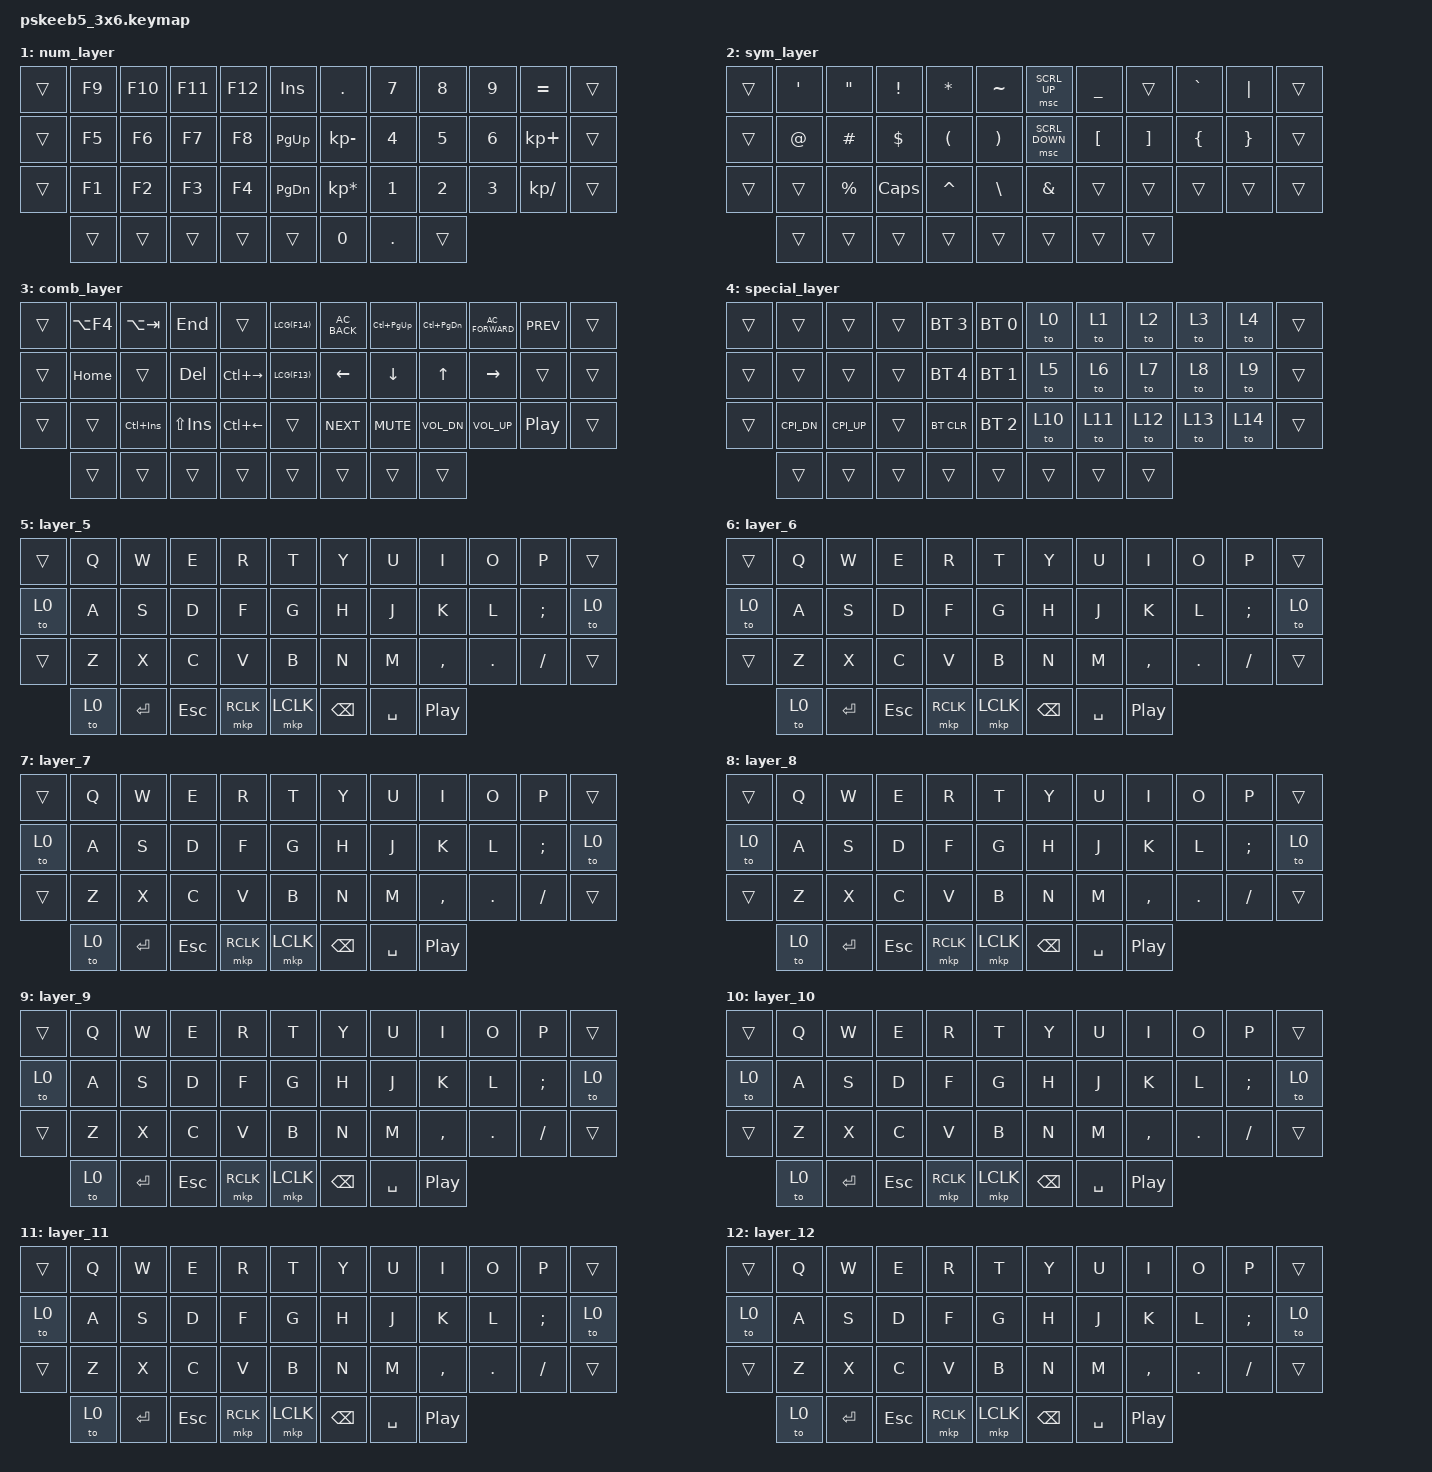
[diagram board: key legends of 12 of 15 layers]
// Copyright (c) 2022 The ZMK Contributors
// SPDX-License-Identifier: MIT

#include <behaviors.dtsi>
#include <dt-bindings/zmk/keys.h>
#include <dt-bindings/zmk/mouse.h>
#include <dt-bindings/zmk/bt.h>

// Home row mods macro
#define HRML(k1,k2,k3,k4) &ht LALT k1  &ht LSHFT k2  &ht LGUI k3  &ht LCTRL k4
#define HRMR(k1,k2,k3,k4) &ht RCTRL k1  &ht RGUI k2  &ht RSHFT k3  &ht RALT k4
#define LCS(keycode) APPLY_MODS(MOD_LCTL | MOD_LSFT, keycode)
#define LCG(keycode) APPLY_MODS(MOD_LCTL | MOD_LGUI, keycode)

// Rotary Endocer for mouse scrolling
#define ROT_MSC_VAL 280
#define ROT_MSC_SUP MOVE_Y(ROT_MSC_VAL)
#define ROT_MSC_SDN MOVE_Y(-ROT_MSC_VAL)
#define ROT_MSC_SLT MOVE_X(-ROT_MSC_VAL)
#define ROT_MSC_SRT MOVE_X(ROT_MSC_VAL)


/ {
// ╭──────┬──────┬──────┬──────┬──────┬──────╮  ╭──────┬──────┬──────┬──────┬──────┬──────╮
//    00     01     02     03     04     05        06     07     08     09     10     11
// ├──────┼──────┼──────┼──────┼──────┼──────┤  ├──────┼──────┼──────┼──────┼──────┼──────┤
//    12     13     14     15     16     17        18     19     20     21     22     23
// ├──────┼──────┼──────┼──────┼──────┼──────┤  ├──────┼──────┼──────┼──────┼──────┼──────┤
//    24     25     26     27     28     29        30     31     32     33     34     35
// ╰──────┴──────┴──────┼──────┼──────┼──────┤  ├──────┼──────┼──────┴──────┴──────┴──────╯
//                  36     37     38     39        40     41     42     43
//               ╰──────┴──────┴──────┴──────╯  ╰──────┴──────┴──────┴──────╯
    behaviors {
        ht: hold_tap {
            display-name = "Hold Tap";
            label = "hold_tap";
            compatible = "zmk,behavior-hold-tap";
            #binding-cells = <2>;
            flavor = "balanced";
            tapping-term-ms = <220>;
            quick-tap-ms = <200>;
            // global-quick-tap;
            tap-ms = <20>;
            bindings = <&kp>, <&kp>;
        };
        lt: layer_tap {
            display-name = "Layer Tap";
            compatible = "zmk,behavior-hold-tap";
            label = "LAYER_TAP";
            #binding-cells = <2>;
            // flavor = "balanced";
            tapping-term-ms = <200>;
            quick-tap-ms = <200>;
            // global-quick-tap;
            tap-ms = <20>;
            bindings = <&mo>, <&kp>;
        };
        rot_msc: sensor_rotate_msc {
            compatible = "zmk,behavior-sensor-rotate-var";
            #sensor-binding-cells = <2>;
            bindings = <&msc>, <&msc>;
            tap-ms = <20>;
        };
    };


    combos {
        compatible = "zmk,combos";
        combo_tab {
            timeout-ms = <50>;
            key-positions = <3 4>;
            bindings = <&kp TAB>;
        };
        middle_click {
            timeout-ms = <50>;
            key-positions = <39 40>;
            bindings = <&mkp MCLK>;
        };
    };

    conditional_layers {
        compatible = "zmk,conditional-layers";
        special_layer {
            if-layers = <2 3>;
            then-layer = <4>;
        };
    };

    keymap {
        compatible = "zmk,keymap";
        default_layer {
            bindings = <
        //╭──────────┬──────────┬──────────┬──────────┬──────────┬──────────╮   ╭──────────┬──────────┬──────────┬──────────┬──────────┬──────────╮
        //│  `       │  Q       │  W       │  E       │  R       │  T       │   │  Y       │  U       │  I       │  O       │  P       │ BSPC     │
            &kp GRAVE  &kp Q      &kp W      &kp E      &kp R      &kp T          &kp Y      &kp U      &kp I      &kp O      &kp P      &kp BSPC
        //├──────────┼──────────┼──────────┼──────────┼──────────┼──────────┤   ├──────────┼──────────┼──────────┼──────────┼──────────┼──────────┤
        //│  TAB     │  A       │  S       │  D       │  F       │  G       │   │  H       │  J       │  K       │  L       │ ; :      │ ENTER    │
            &kp TAB    HRML(A,        S,         D,         F)     &lt 3 G         &lt 3 H    HRMR(J,        K,         L,        SEMI)     &kp ENTER
        //├──────────┼──────────┼──────────┼──────────┼──────────┼──────────┤   ├──────────┼──────────┼──────────┼──────────┼──────────┼──────────┤
        //│  LEFT    │  Z       │  X       │  C       │  V       │  B       │   │  N       │  M       │ , <      │ . >      │ / ?      │ RIGHT    │
            &kp LEFT   HRMR(Z,        X,        C,          V)     &kp B          &kp N      HRML(M,        COMMA,     DOT,      FSLH)      &kp RIGHT
        //╰──────────┴──────────┴──────────┼──────────┼──────────┼──────────┤   ├──────────┼──────────┼──────────┴──────────┴──────────┴──────────╯
        //                              &kp K_POWER  &lt 1 ENTER  &lt 3 ESC  &mkp LCLK     &mkp RCLK  &lt 2 BSPC &mt LSHFT SPACE  &kp C_PP
                    &kp K_POWER  &lt 1 ENTER  &lt 3 ESC  &mkp LCLK     &mkp RCLK  &lt 2 BSPC &mt LSHFT SPACE  &kp C_PP
        //                                 ╰──────────┴──────────┴──────────╯   ╰──────────┴──────────╯
            >;
            // sensor-bindings = <&rot_msc ROT_MSC_SUP ROT_MSC_SDN &rot_msc ROT_MSC_SLT ROT_MSC_SRT>;
            sensor-bindings = <&inc_dec_kp C_VOL_DN C_VOL_UP &inc_dec_kp LEFT RIGHT>;
        };

        num_layer {
            bindings = <
            &trans      &kp F9     &kp F10    &kp F11    &kp F12    &kp INS        &kp DOT         &kp N7     &kp N8     &kp N9     &kp EQUAL     &trans
            &trans      &kp F5     &kp F6     &kp F7     &kp F8     &kp PG_UP      &kp KP_MINUS    &kp N4     &kp N5     &kp N6     &kp KP_PLUS   &trans
            &trans      &kp F1     &kp F2     &kp F3     &kp F4     &kp PG_DN      &kp KP_MULTIPLY &kp N1     &kp N2     &kp N3     &kp KP_DIVIDE &trans
                        &trans     &trans     &trans     &trans         &trans           &kp N0     &kp DOT       &trans
            >;
            sensor-bindings = <&inc_dec_kp C_VOL_DN C_VOL_UP &inc_dec_kp LEFT RIGHT>;
        };

        sym_layer {
            bindings = <
            &trans      &kp SQT    &kp DQT    &kp EXCL   &kp STAR   &kp TILDE      &msc SCRL_UP   &kp UNDER  &trans     &kp GRAVE  &kp PIPE      &trans
            &trans      &kp AT     &kp HASH   &kp DLLR   &kp LPAR   &kp RPAR       &msc SCRL_DOWN &kp LBKT   &kp RBKT   &kp LBRC   &kp RBRC      &trans
            &trans      &trans     &kp PRCNT  &kp CAPS   &kp CARET  &kp BSLH       &kp AMPS       &trans     &trans     &trans     &trans        &trans
                        &trans     &trans     &trans     &trans         &trans       &trans     &trans     &trans
            >;
            sensor-bindings = <&inc_dec_kp C_VOL_DN C_VOL_UP &inc_dec_kp LEFT RIGHT>;
        };

        comb_layer {
            bindings = <
            &trans      &kp LA(F4)    &kp LA(TAB)   &kp END    &trans         &kp LCG(F14)     &kp C_AC_BACK  &kp LC(PG_UP)   &kp LC(PG_DN) &kp C_AC_FORWARD &kp C_PREV  &trans
            &trans      &kp HOME      &trans         &kp DEL    &kp LC(RIGHT)  &kp LCG(F13)     &kp LEFT       &kp DOWN        &kp UP        &kp RIGHT        &trans       &trans
            &trans      &trans        &kp LC(INS)    &kp LS(INS) &kp LC(LEFT)  &trans           &kp C_NEXT     &kp C_MUTE      &kp C_VOL_DN  &kp C_VOL_UP     &kp C_PP     &trans
                        &trans        &trans         &trans     &trans         &trans           &trans         &trans          &trans
            >;
            sensor-bindings = <&inc_dec_kp C_VOL_DN C_VOL_UP &inc_dec_kp LEFT RIGHT>;
        };

        special_layer {
            bindings = <
            &trans      &trans        &trans     &trans         &bt BT_SEL 3   &bt BT_SEL 0      &to 0     &to 1       &to 2      &to 3      &to 4      &trans
            &trans      &trans        &trans     &trans         &bt BT_SEL 4   &bt BT_SEL 1      &to 5     &to 6       &to 7      &to 8      &to 9      &trans
            &trans      CPI_DN        CPI_UP     &trans         &bt BT_CLR     &bt BT_SEL 2      &to 10    &to 11      &to 12     &to 13     &to 14     &trans
                        &trans        &trans     &trans         &trans         &trans            &trans    &trans      &trans
            >;
            sensor-bindings = <&inc_dec_kp C_VOL_DN C_VOL_UP &inc_dec_kp LEFT RIGHT>;
        };

        layer_5 {
            bindings = <
            &trans      &kp Q        &kp W      &kp E      &kp R      &kp T          &kp Y      &kp U      &kp I      &kp O      &kp P      &trans
            &to 0       &kp A        &kp S      &kp D      &kp F      &kp G          &kp H      &kp J      &kp K      &kp L      &kp SEMI   &to 0
            &trans      &kp Z        &kp X      &kp C      &kp V      &kp B          &kp N      &kp M      &kp COMMA  &kp DOT    &kp FSLH   &trans
                        &to 0        &kp ENTER  &kp ESC    &mkp RCLK       &mkp LCLK  &kp BSPC   &kp SPACE  &kp C_PP
            >;
            sensor-bindings = <&inc_dec_kp C_VOL_DN C_VOL_UP &inc_dec_kp LEFT RIGHT>;
        };

        layer_6 {
            bindings = <
            &trans      &kp Q        &kp W      &kp E      &kp R      &kp T          &kp Y      &kp U      &kp I      &kp O      &kp P      &trans
            &to 0       &kp A        &kp S      &kp D      &kp F      &kp G          &kp H      &kp J      &kp K      &kp L      &kp SEMI   &to 0
            &trans      &kp Z        &kp X      &kp C      &kp V      &kp B          &kp N      &kp M      &kp COMMA  &kp DOT    &kp FSLH   &trans
                        &to 0        &kp ENTER  &kp ESC    &mkp RCLK       &mkp LCLK  &kp BSPC   &kp SPACE  &kp C_PP
            >;
            sensor-bindings = <&inc_dec_kp C_VOL_DN C_VOL_UP &inc_dec_kp LEFT RIGHT>;
        };

        layer_7 {
            bindings = <
            &trans      &kp Q        &kp W      &kp E      &kp R      &kp T          &kp Y      &kp U      &kp I      &kp O      &kp P      &trans
            &to 0       &kp A        &kp S      &kp D      &kp F      &kp G          &kp H      &kp J      &kp K      &kp L      &kp SEMI   &to 0
            &trans      &kp Z        &kp X      &kp C      &kp V      &kp B          &kp N      &kp M      &kp COMMA  &kp DOT    &kp FSLH   &trans
                        &to 0        &kp ENTER  &kp ESC    &mkp RCLK       &mkp LCLK  &kp BSPC   &kp SPACE  &kp C_PP
            >;
            sensor-bindings = <&inc_dec_kp C_VOL_DN C_VOL_UP &inc_dec_kp LEFT RIGHT>;
        };

        layer_8 {
            bindings = <
            &trans      &kp Q        &kp W      &kp E      &kp R      &kp T          &kp Y      &kp U      &kp I      &kp O      &kp P      &trans
            &to 0       &kp A        &kp S      &kp D      &kp F      &kp G          &kp H      &kp J      &kp K      &kp L      &kp SEMI   &to 0
            &trans      &kp Z        &kp X      &kp C      &kp V      &kp B          &kp N      &kp M      &kp COMMA  &kp DOT    &kp FSLH   &trans
                        &to 0        &kp ENTER  &kp ESC    &mkp RCLK       &mkp LCLK  &kp BSPC   &kp SPACE  &kp C_PP
            >;
            sensor-bindings = <&inc_dec_kp C_VOL_DN C_VOL_UP &inc_dec_kp LEFT RIGHT>;
        };

        layer_9 {
            bindings = <
            &trans      &kp Q        &kp W      &kp E      &kp R      &kp T          &kp Y      &kp U      &kp I      &kp O      &kp P      &trans
            &to 0       &kp A        &kp S      &kp D      &kp F      &kp G          &kp H      &kp J      &kp K      &kp L      &kp SEMI   &to 0
            &trans      &kp Z        &kp X      &kp C      &kp V      &kp B          &kp N      &kp M      &kp COMMA  &kp DOT    &kp FSLH   &trans
                        &to 0        &kp ENTER  &kp ESC    &mkp RCLK       &mkp LCLK  &kp BSPC   &kp SPACE  &kp C_PP
            >;
            sensor-bindings = <&inc_dec_kp C_VOL_DN C_VOL_UP &inc_dec_kp LEFT RIGHT>;
        };

        layer_10 {
            bindings = <
            &trans      &kp Q        &kp W      &kp E      &kp R      &kp T          &kp Y      &kp U      &kp I      &kp O      &kp P      &trans
            &to 0       &kp A        &kp S      &kp D      &kp F      &kp G          &kp H      &kp J      &kp K      &kp L      &kp SEMI   &to 0
            &trans      &kp Z        &kp X      &kp C      &kp V      &kp B          &kp N      &kp M      &kp COMMA  &kp DOT    &kp FSLH   &trans
                        &to 0        &kp ENTER  &kp ESC    &mkp RCLK       &mkp LCLK  &kp BSPC   &kp SPACE  &kp C_PP
            >;
            sensor-bindings = <&inc_dec_kp C_VOL_DN C_VOL_UP &inc_dec_kp LEFT RIGHT>;
        };

        layer_11 {
            bindings = <
            &trans      &kp Q        &kp W      &kp E      &kp R      &kp T          &kp Y      &kp U      &kp I      &kp O      &kp P      &trans
            &to 0       &kp A        &kp S      &kp D      &kp F      &kp G          &kp H      &kp J      &kp K      &kp L      &kp SEMI   &to 0
            &trans      &kp Z        &kp X      &kp C      &kp V      &kp B          &kp N      &kp M      &kp COMMA  &kp DOT    &kp FSLH   &trans
                        &to 0        &kp ENTER  &kp ESC    &mkp RCLK       &mkp LCLK  &kp BSPC   &kp SPACE  &kp C_PP
            >;
            sensor-bindings = <&inc_dec_kp C_VOL_DN C_VOL_UP &inc_dec_kp LEFT RIGHT>;
        };

        layer_12 {
            bindings = <
            &trans      &kp Q        &kp W      &kp E      &kp R      &kp T          &kp Y      &kp U      &kp I      &kp O      &kp P      &trans
            &to 0       &kp A        &kp S      &kp D      &kp F      &kp G          &kp H      &kp J      &kp K      &kp L      &kp SEMI   &to 0
            &trans      &kp Z        &kp X      &kp C      &kp V      &kp B          &kp N      &kp M      &kp COMMA  &kp DOT    &kp FSLH   &trans
                        &to 0        &kp ENTER  &kp ESC    &mkp RCLK       &mkp LCLK  &kp BSPC   &kp SPACE  &kp C_PP
            >;
            sensor-bindings = <&inc_dec_kp C_VOL_DN C_VOL_UP &inc_dec_kp LEFT RIGHT>;
        };

        layer_13 {
            bindings = <
            &trans      &kp Q        &kp W      &kp E      &kp R      &kp T          &kp Y      &kp U      &kp I      &kp O      &kp P      &trans
            &to 0       &kp A        &kp S      &kp D      &kp F      &kp G          &kp H      &kp J      &kp K      &kp L      &kp SEMI   &to 0
            &trans      &kp Z        &kp X      &kp C      &kp V      &kp B          &kp N      &kp M      &kp COMMA  &kp DOT    &kp FSLH   &trans
                        &to 0        &kp ENTER  &kp ESC    &mkp RCLK       &mkp LCLK  &kp BSPC   &kp SPACE  &kp C_PP
            >;
            sensor-bindings = <&inc_dec_kp C_VOL_DN C_VOL_UP &inc_dec_kp LEFT RIGHT>;
        };

        layer_14 {
            bindings = <
            &trans      &kp Q        &kp W      &kp E      &kp R      &kp T          &kp Y      &kp U      &kp I      &kp O      &kp P      &trans
            &to 0       &kp A        &kp S      &kp D      &kp F      &kp G          &kp H      &kp J      &kp K      &kp L      &kp SEMI   &to 0
            &trans      &kp Z        &kp X      &kp C      &kp V      &kp B          &kp N      &kp M      &kp COMMA  &kp DOT    &kp FSLH   &trans
                        &to 0        &kp ENTER  &kp ESC    &mkp RCLK       &mkp LCLK  &kp BSPC   &kp SPACE  &kp C_PP
            >;
            sensor-bindings = <&inc_dec_kp C_VOL_DN C_VOL_UP &inc_dec_kp LEFT RIGHT>;
        };
    };
};
